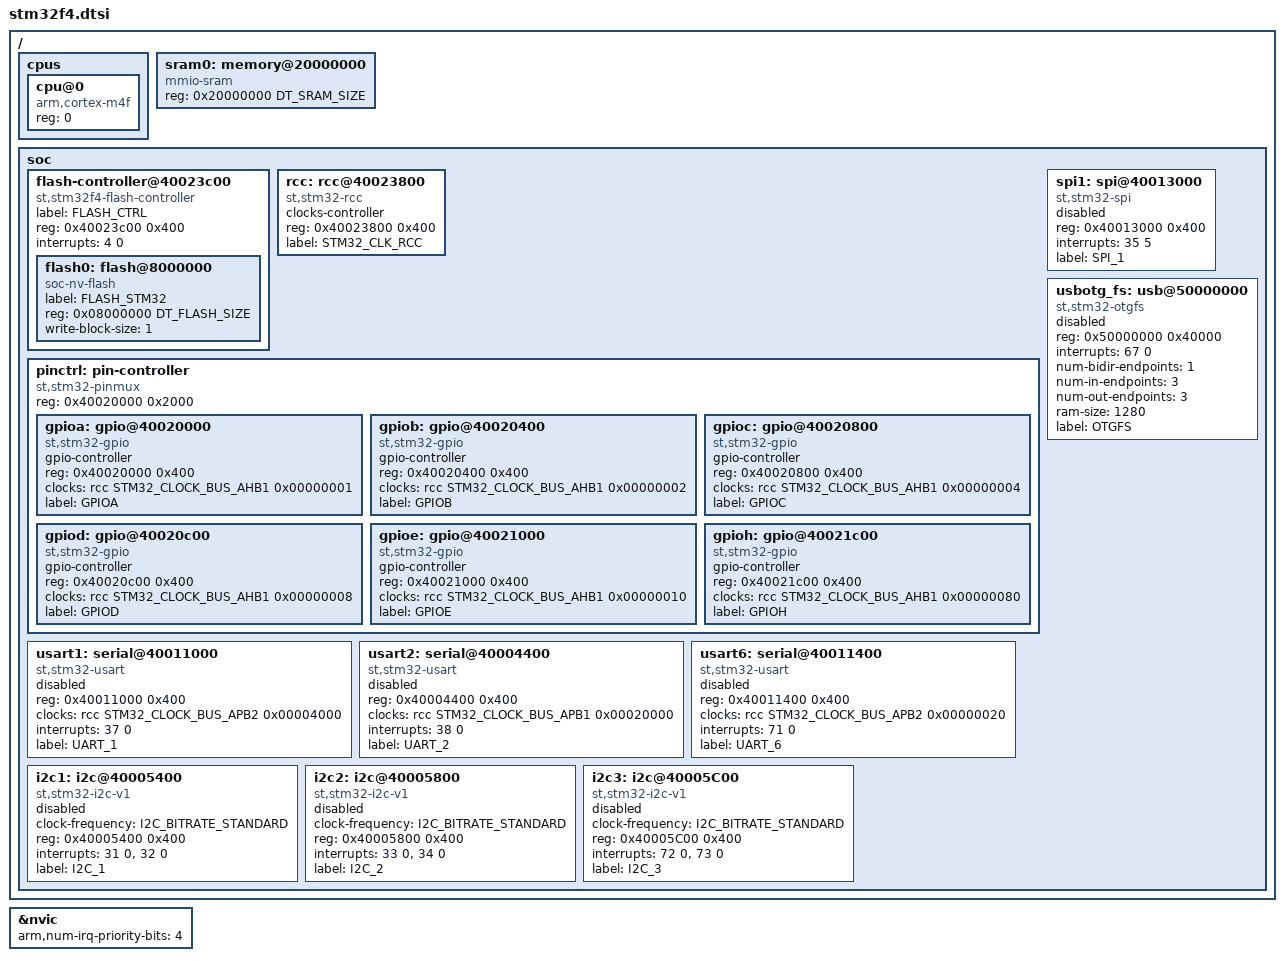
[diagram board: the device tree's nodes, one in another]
/*
 * Copyright (c) 2017 Linaro Limited
 *
 * SPDX-License-Identifier: Apache-2.0
 */

#include <arm/armv7-m.dtsi>
#include <st/stm32f4-pinctrl.dtsi>
#include <st/mem.h>
#include <dt-bindings/clock/stm32_clock.h>
#include <dt-bindings/i2c/i2c.h>

/ {
	cpus {
		#address-cells = <1>;
		#size-cells = <0>;

		cpu@0 {
			device_type = "cpu";
			compatible = "arm,cortex-m4f";
			reg = <0>;
		};
	};

	sram0: memory@20000000 {
		device_type = "memory";
		compatible = "mmio-sram";
		reg = <0x20000000 DT_SRAM_SIZE>;
	};

	soc {
		flash-controller@40023c00 {
			compatible = "st,stm32f4-flash-controller";
			label = "FLASH_CTRL";
			reg = <0x40023c00 0x400>;
			interrupts = <4 0>;

			#address-cells = <1>;
			#size-cells = <1>;

			flash0: flash@8000000 {
				compatible = "soc-nv-flash";
				label = "FLASH_STM32";
				reg = <0x08000000 DT_FLASH_SIZE>;

				write-block-size = <1>;
			};
		};

		rcc: rcc@40023800 {
			compatible = "st,stm32-rcc";
			clocks-controller;
			#clocks-cells = <2>;
			reg = <0x40023800 0x400>;
			label = "STM32_CLK_RCC";
		};

		pinctrl: pin-controller {
			compatible = "st,stm32-pinmux";
			#address-cells = <1>;
			#size-cells = <1>;
			reg = <0x40020000 0x2000>;

			gpioa: gpio@40020000 {
				compatible = "st,stm32-gpio";
				gpio-controller;
				#gpio-cells = <2>;
				reg = <0x40020000 0x400>;
				clocks = <&rcc STM32_CLOCK_BUS_AHB1 0x00000001>;
				label = "GPIOA";
			};

			gpiob: gpio@40020400 {
				compatible = "st,stm32-gpio";
				gpio-controller;
				#gpio-cells = <2>;
				reg = <0x40020400 0x400>;
				clocks = <&rcc STM32_CLOCK_BUS_AHB1 0x00000002>;
				label = "GPIOB";
			};

			gpioc: gpio@40020800 {
				compatible = "st,stm32-gpio";
				gpio-controller;
				#gpio-cells = <2>;
				reg = <0x40020800 0x400>;
				clocks = <&rcc STM32_CLOCK_BUS_AHB1 0x00000004>;
				label = "GPIOC";
			};

			gpiod: gpio@40020c00 {
				compatible = "st,stm32-gpio";
				gpio-controller;
				#gpio-cells = <2>;
				reg = <0x40020c00 0x400>;
				clocks = <&rcc STM32_CLOCK_BUS_AHB1 0x00000008>;
				label = "GPIOD";
			};

			gpioe: gpio@40021000 {
				compatible = "st,stm32-gpio";
				gpio-controller;
				#gpio-cells = <2>;
				reg = <0x40021000 0x400>;
				clocks = <&rcc STM32_CLOCK_BUS_AHB1 0x00000010>;
				label = "GPIOE";
			};

			gpioh: gpio@40021c00 {
				compatible = "st,stm32-gpio";
				gpio-controller;
				#gpio-cells = <2>;
				reg = <0x40021c00 0x400>;
				clocks = <&rcc STM32_CLOCK_BUS_AHB1 0x00000080>;
				label = "GPIOH";
			};
		};


		usart1: serial@40011000 {
			compatible = "st,stm32-usart", "st,stm32-uart";
			reg = <0x40011000 0x400>;
			clocks = <&rcc STM32_CLOCK_BUS_APB2 0x00004000>;
			interrupts = <37 0>;
			status = "disabled";
			label = "UART_1";
		};

		usart2: serial@40004400 {
			compatible = "st,stm32-usart", "st,stm32-uart";
			reg = <0x40004400 0x400>;
			clocks = <&rcc STM32_CLOCK_BUS_APB1 0x00020000>;
			interrupts = <38 0>;
			status = "disabled";
			label = "UART_2";
		};

		usart6: serial@40011400 {
			compatible = "st,stm32-usart", "st,stm32-uart";
			reg = <0x40011400 0x400>;
			clocks = <&rcc STM32_CLOCK_BUS_APB2 0x00000020>;
			interrupts = <71 0>;
			status = "disabled";
			label = "UART_6";
		};

		i2c1: i2c@40005400 {
			compatible = "st,stm32-i2c-v1";
			clock-frequency = <I2C_BITRATE_STANDARD>;
			#address-cells = <1>;
			#size-cells = <0>;
			reg = <0x40005400 0x400>;
			interrupts = <31 0>, <32 0>;
			interrupt-names = "event", "error";
			status = "disabled";
			label= "I2C_1";
		};

		i2c2: i2c@40005800 {
			compatible = "st,stm32-i2c-v1";
			clock-frequency = <I2C_BITRATE_STANDARD>;
			#address-cells = <1>;
			#size-cells = <0>;
			reg = <0x40005800 0x400>;
			interrupts = <33 0>, <34 0>;
			interrupt-names = "event", "error";
			status = "disabled";
			label= "I2C_2";
		};

		i2c3: i2c@40005C00 {
			compatible = "st,stm32-i2c-v1";
			clock-frequency = <I2C_BITRATE_STANDARD>;
			#address-cells = <1>;
			#size-cells = <0>;
			reg = <0x40005C00 0x400>;
			interrupts = <72 0>, <73 0>;
			interrupt-names = "event", "error";
			status = "disabled";
			label= "I2C_3";
		};

		spi1: spi@40013000 {
			compatible = "st,stm32-spi";
			#address-cells = <1>;
			#size-cells = <0>;
			reg = <0x40013000 0x400>;
			interrupts = <35 5>;
			status = "disabled";
			label = "SPI_1";
		};

		usbotg_fs: usb@50000000 {
			compatible = "st,stm32-otgfs";
			reg = <0x50000000 0x40000>;
			interrupts = <67 0>;
			interrupt-names = "otgfs";
			num-bidir-endpoints = <1>;
			num-in-endpoints = <3>;
			num-out-endpoints = <3>;
			ram-size = <1280>;
			status = "disabled";
			label= "OTGFS";
		};
	};
};

&nvic {
	arm,num-irq-priority-bits = <4>;
};
